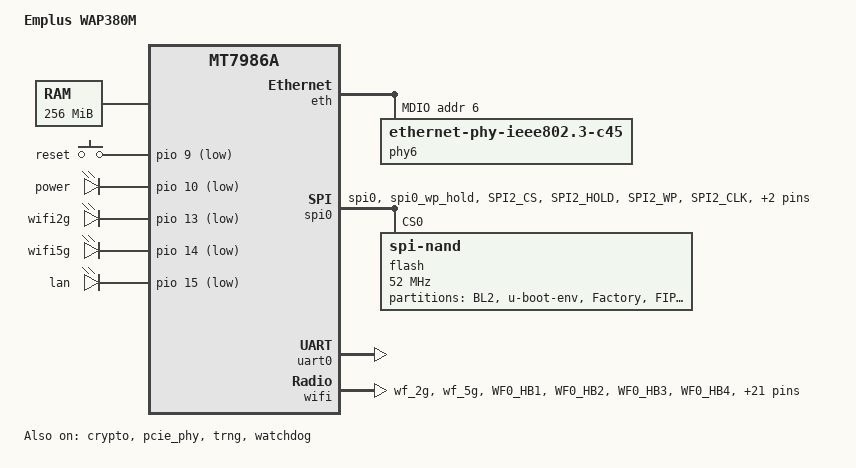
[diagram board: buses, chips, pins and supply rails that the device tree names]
// SPDX-License-Identifier: (GPL-2.0 OR MIT)

/dts-v1/;
#include <dt-bindings/input/input.h>
#include <dt-bindings/gpio/gpio.h>
#include <dt-bindings/leds/common.h>

#include "mt7986a.dtsi"
/ {
	model = "Emplus WAP380M";
	compatible = "emplus,wap380m", "mediatek,mt7986a";
	chosen {
		bootargs = "console=ttyS0,115200n1 loglevel=8  \
				earlycon=uart8250,mmio32,0x11002000";
	};

	memory@40000000 {
		reg = <0 0x40000000 0 0x10000000>;
		device_type = "memory";
	};

	gpio-keys {
		compatible = "gpio-keys";
		reset {
			label = "reset";
			linux,code = <KEY_RESTART>;
			gpios = <&pio 9 GPIO_ACTIVE_LOW>;
		};
	};

	leds {
		compatible = "gpio-leds";

		power {
			label = "power";
			gpios = <&pio 10 GPIO_ACTIVE_LOW>;
			linux,default-trigger = "timer";
			default-state = "on";
		};

		wifi2g {
			label = "wifi2g";
			gpios = <&pio 13 GPIO_ACTIVE_LOW>;
		};

		wifi5g {
			label = "wifi5g";
			gpios = <&pio 14 GPIO_ACTIVE_LOW>;
		};

		lan {
			label = "lan";
			gpios = <&pio 15 GPIO_ACTIVE_LOW>;
		};
	};


};

&crypto {
	status = "okay";
};

&eth {
	status = "okay";

	mac@1 {
		compatible = "mediatek,eth-mac";
		reg = <1>;
		phy-mode = "2500base-x";
		phy-handle = <&phy6>;
		nvmem-cells = <&macaddr>;
		nvmem-cell-names = "mac-address";
	};

	mdio: mdio-bus {
		#address-cells = <1>;
		#size-cells = <0>;

		reset-gpios = <&pio 6 1>;
		reset-delay-us = <600>;


		phy6: phy@6 {
			compatible = "ethernet-phy-ieee802.3-c45";
			reg = <6>;
		};
	};
};

&pcie_phy {
	status = "okay";
};

&pio {
	spi_flash_pins: spi-flash-pins-33-to-38 {
		mux {
			function = "spi";
			groups = "spi0", "spi0_wp_hold";
		};
		conf-pu {
			pins = "SPI2_CS", "SPI2_HOLD", "SPI2_WP";
			drive-strength = <8>;
			mediatek,pull-up-adv = <0>; /* bias-disable */
		};
		conf-pd {
			pins = "SPI2_CLK", "SPI2_MOSI", "SPI2_MISO";
			drive-strength = <8>;
			mediatek,pull-down-adv = <0>; /* bias-disable */
		};
	};

	wf_2g_5g_pins: wf_2g_5g-pins {
		mux {
			function = "wifi";
			groups = "wf_2g", "wf_5g";
		};
		conf {
			pins = "WF0_HB1", "WF0_HB2", "WF0_HB3", "WF0_HB4",
			       "WF0_HB0", "WF0_HB0_B", "WF0_HB5", "WF0_HB6",
			       "WF0_HB7", "WF0_HB8", "WF0_HB9", "WF0_HB10",
			       "WF0_TOP_CLK", "WF0_TOP_DATA", "WF1_HB1",
			       "WF1_HB2", "WF1_HB3", "WF1_HB4", "WF1_HB0",
			       "WF1_HB5", "WF1_HB6", "WF1_HB7", "WF1_HB8",
			       "WF1_TOP_CLK", "WF1_TOP_DATA";
			drive-strength = <4>;
		};
	};

	wf_dbdc_pins: wf_dbdc-pins {
		mux {
			function = "wifi";
			groups = "wf_dbdc";
		};
		conf {
			pins = "WF0_HB1", "WF0_HB2", "WF0_HB3", "WF0_HB4",
			       "WF0_HB0", "WF0_HB0_B", "WF0_HB5", "WF0_HB6",
			       "WF0_HB7", "WF0_HB8", "WF0_HB9", "WF0_HB10",
			       "WF0_TOP_CLK", "WF0_TOP_DATA", "WF1_HB1",
			       "WF1_HB2", "WF1_HB3", "WF1_HB4", "WF1_HB0",
			       "WF1_HB5", "WF1_HB6", "WF1_HB7", "WF1_HB8",
			       "WF1_TOP_CLK", "WF1_TOP_DATA";
			drive-strength = <4>;
		};
	};
};

&spi0 {
	pinctrl-names = "default";
	pinctrl-0 = <&spi_flash_pins>;
	status = "okay";

	flash@0 {
		compatible = "spi-nand";
		reg = <0>;
		#address-cells = <1>;
		#size-cells = <1>;
		spi-max-frequency = <52000000>;
		spi-rx-bus-width = <4>;
		spi-tx-bus-width = <4>;
		mediatek,nmbm;
		mediatek,bmt-max-ratio = <1>;
		mediatek,bmt-max-reserved-blocks = <64>;

		partitions {
			compatible = "fixed-partitions";
			#address-cells = <1>;
			#size-cells = <1>;

			partition@0 {
				reg = <0x0 0x100000>;
				label = "BL2";
				read-only;
			};

			partition@100000 {
				reg = <0x100000 0x80000>;
				label = "u-boot-env";
			};

			partition@180000 {
				compatible = "nvmem-cells";
				reg = <0x180000 0x200000>;
				label = "Factory";

				nvmem-layout {
					compatible = "fixed-layout";
					#address-cells = <1>;
					#size-cells = <1>;

					eeprom: eeprom@0 {
						reg = <0x0 0x1000>;
					};

					macaddr: macaddr@24 {
						reg = <0x24 0x6>;
					};
				};
			};

			partition@380000 {
				label = "FIP";
				reg = <0x380000 0x0200000>;
			};

			partition@580000 {
				label = "ubi";
				reg = <0x580000 0x6E00000>;
			};

			partition@7380000 {
				label = "ubi_1";
				reg = <0x7380000 0x6E00000>;
			};

			partition@E180000 {
				label = "cert"; //384KB
				reg = <0xE180000 0x0060000>;
			};

			partition@E1E0000 {
				label = "userconfig"; //640KB
				reg = <0xE1E0000 0x00a0000>;
			};

			partition@E280000 {
				label = "crashdump"; //384KB
				reg = <0xE280000 0x0060000>;
			};


		};
	};
};
&trng {
	status = "okay";
};

&uart0 {
	status = "okay";
};

&watchdog {
	status = "okay";
};

&wifi {
	pinctrl-names = "default", "dbdc";
	pinctrl-0 = <&wf_2g_5g_pins>;
	pinctrl-1 = <&wf_dbdc_pins>;
	nvmem-cells = <&eeprom>;
	nvmem-cell-names = "eeprom";
	status = "okay";
};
